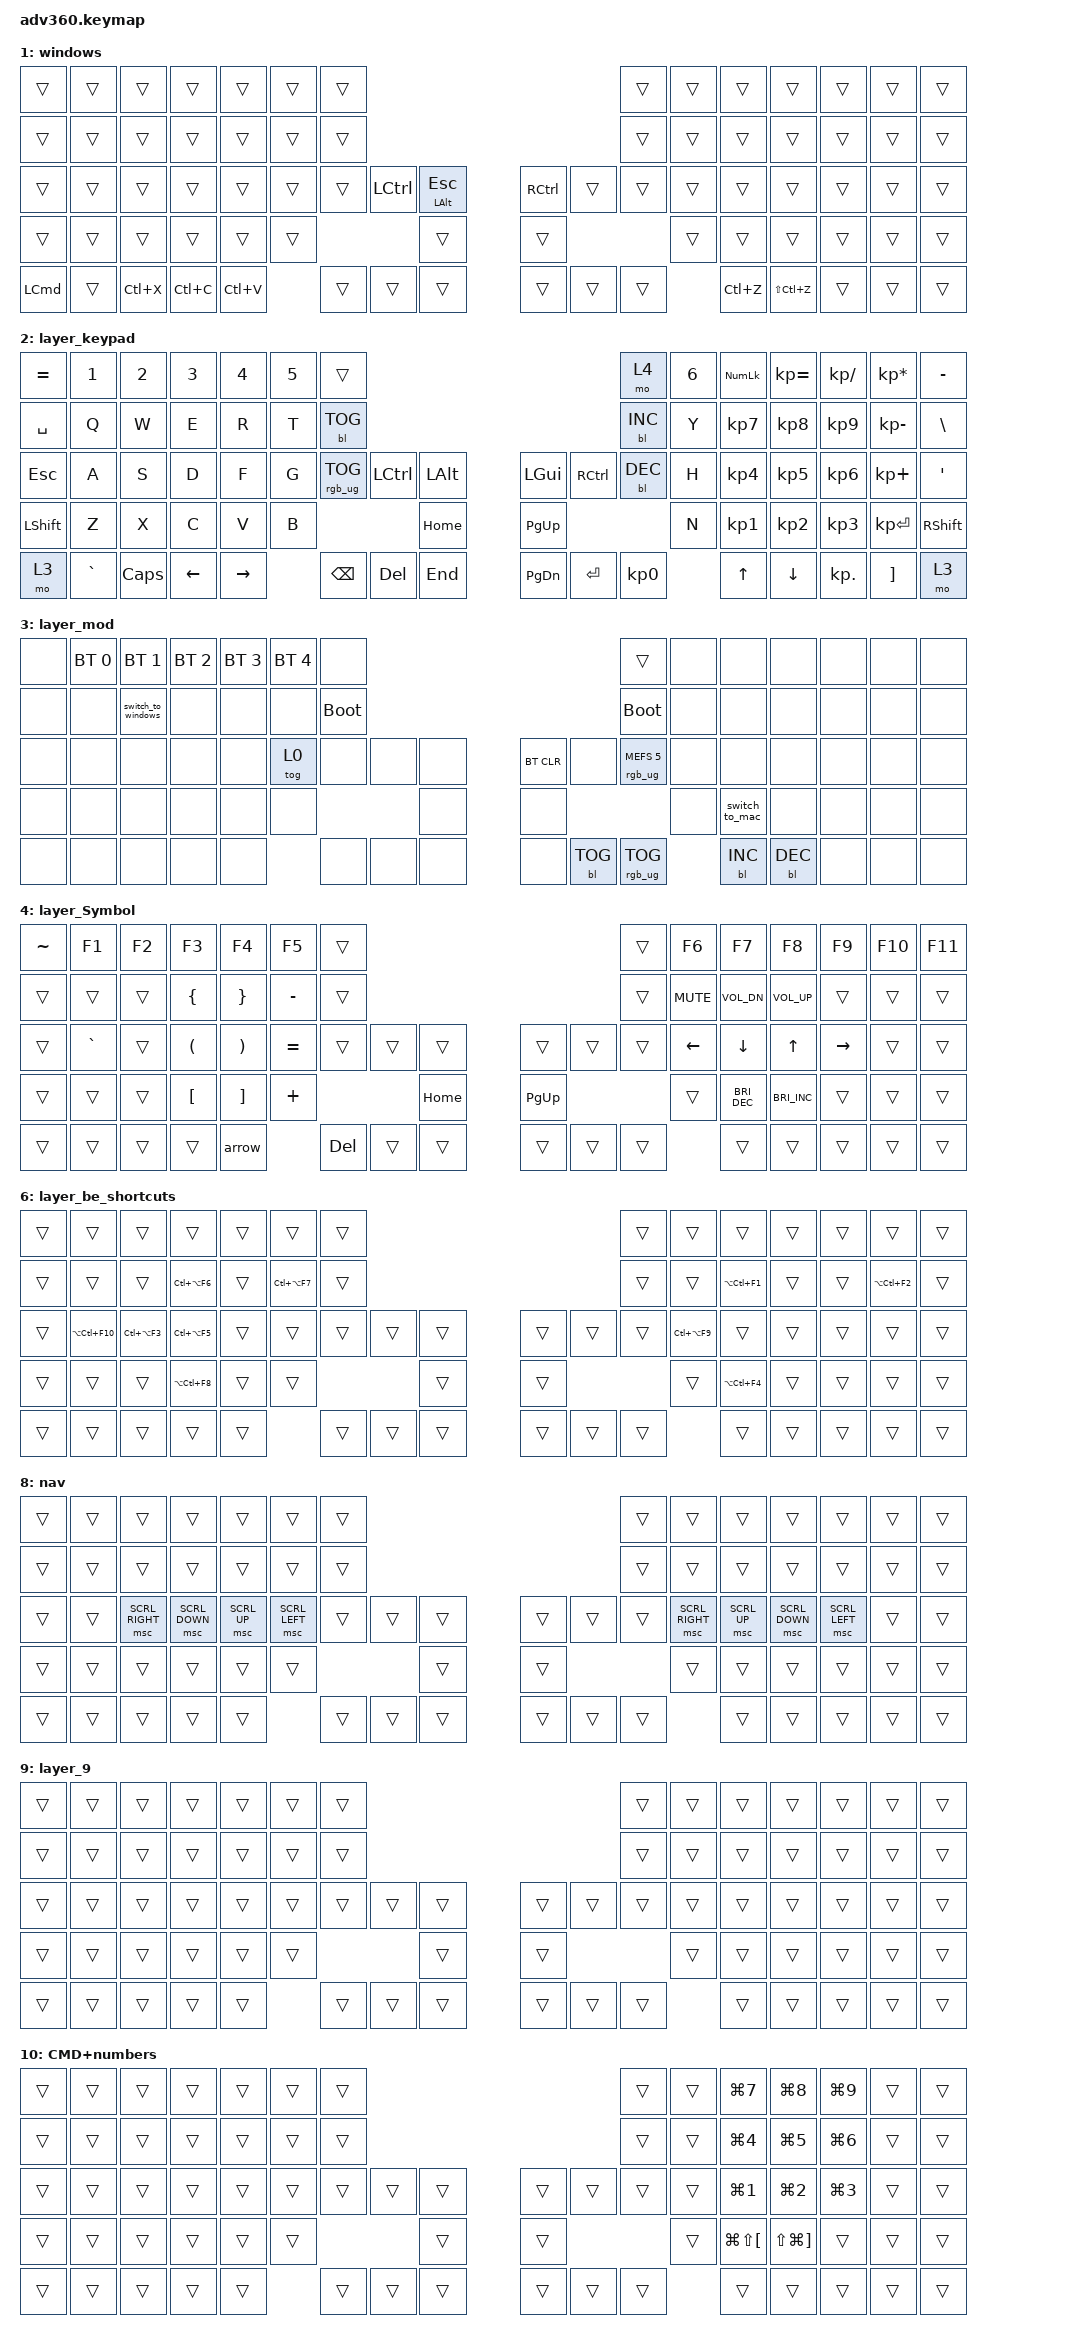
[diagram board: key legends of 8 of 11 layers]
/*
 * Copyright (c) 2020 The ZMK Contributors
 *
 * SPDX-License-Identifier: MIT
 */
/* THIS FILE WAS GENERATED!
 *
 * This file was generated automatically. You may or may not want to
 * edit it directly.
 */

#define ZMK_POINTING_DEFAULT_SCRL_VAL 40

#include <dt-bindings/zmk/mouse.h>
#include <dt-bindings/zmk/stp.h>
#include <behaviors.dtsi>
#include <dt-bindings/zmk/backlight.h>
#include <dt-bindings/zmk/bt.h>
#include <dt-bindings/zmk/keys.h>
#include <dt-bindings/zmk/pointing.h>
#include <dt-bindings/zmk/rgb.h>

&lt {
    quick-tap-ms = <150>;
    tapping-term-ms = <100>;
};

/ {
    behaviors {
        #include "macros.dtsi"
      #include "version.dtsi"
      #ifndef VERSION_MACRO

        macro_ver: macro_ver {
            compatible = "zmk,behavior-macro";
            label = "macro_version";
            #binding-cells = <0>;
            bindings = <&kp RET>;
        };

        #endif

        hm: homerow_mods {
            compatible = "zmk,behavior-hold-tap";
            label = "HOMEROW_MODS";
            #binding-cells = <2>;
            tapping-term-ms = <200>;
            quick_tap_ms = <175>;
            flavor = "tap-preferred";
            bindings = <&kp>, <&kp>;
        };

        tap_dance_shift_caps_word: tap_dance_shift_caps_word {
            compatible = "zmk,behavior-tap-dance";
            label = "TAP_DANCE_SHIFT_CAPS_WORD";
            #binding-cells = <0>;
            bindings = <&kp LEFT_SHIFT>, <&caps_word>;
        };

        urob: urob {
            compatible = "zmk,behavior-hold-tap";
            label = "UROB";
            bindings = <&kp>, <&kp>;

            #binding-cells = <2>;
            tapping-term-ms = <150>;
            quick-tap-ms = <175>;
            require-prior-idle-ms = <200>;
            flavor = "hold-preferred";
        };

        custom_mt: custom_mt {
            compatible = "zmk,behavior-hold-tap";
            label = "CUSTOM_MT";
            bindings = <&kp>, <&kp>;

            #binding-cells = <2>;
            tapping-term-ms = <200>;
            quick-tap-ms = <175>;
            require-prior-idle-ms = <350>;
            flavor = "hold-preferred";
        };

        pht: positional_hold_tap {
            compatible = "zmk,behavior-hold-tap";
            label = "POSITIONAL_HOLD_TAP";
            bindings = <&kp>, <&kp>;

            #binding-cells = <2>;
            tapping-term-ms = <400>;
            require-prior-idle-ms = <200>;
            quick-tap-ms = <175>;
            flavor = "hold-preferred";

            // hold-trigger-key-positions = <19 29>;    // <---[[the T, A key]]
        };

        mt_rt: mod_tap_retro_tap {
            compatible = "zmk,behavior-hold-tap";
            label = "MOD_TAP_RETRO_TAP";
            bindings = <&kp>, <&kp>;

            #binding-cells = <2>;
            retro-tap;
            flavor = "hold-preferred";
            tapping-term-ms = <200>;
        };

        mt_tp: mod_tap_tap_preferred {
            compatible = "zmk,behavior-hold-tap";
            label = "MOD_TAP_TAP_PREFERRED";
            bindings = <&kp>, <&kp>;

            #binding-cells = <2>;
            flavor = "tap-preferred";
            tapping-term-ms = <200>;
        };

        mt_100ms: mod_tap_100ms {
            compatible = "zmk,behavior-hold-tap";
            label = "MOD_TAP_100ms";
            bindings = <&kp>, <&kp>;

            #binding-cells = <2>;
            flavor = "hold-preferred";
            tapping-term-ms = <150>;
        };

        tap_dance_backspace: tap_dance_backspace {
            compatible = "zmk,behavior-tap-dance";
            label = "TAP_DANCE_BACKSPACE";
            #binding-cells = <0>;
            bindings =
                <&kp BACKSPACE>,
                <&kp LA(BACKSPACE)>,
                <&kp LG(BACKSPACE)>;

            tapping-term-ms = <150>;
        };

        shift_backspace_del_word: shift_backspace_del_word {
            compatible = "zmk,behavior-mod-morph";
            label = "SHIFT_BACKSPACE_DEL_WORD";
            bindings = <&kp BACKSPACE>, <&kp LA(BACKSPACE)>;

            #binding-cells = <0>;
            mods = <(MOD_RSFT)>;
        };
    };

    macros {
        arrow: arrow2 {
            compatible = "zmk,behavior-macro";
            #binding-cells = <0>;
            bindings = <&kp SPACE &kp EQUAL &kp GREATER_THAN &kp SPACE>;
            label = "ARROW2";
        };

        switch_to_windows: windows {
            compatible = "zmk,behavior-macro";
            #binding-cells = <0>;
            bindings = <&tog 1 &bt BT_SEL 2>;
            label = "WINDOWS";
        };

        switch_to_mac: mac {
            compatible = "zmk,behavior-macro";
            #binding-cells = <0>;
            bindings = <&tog 1 &bt BT_SEL 0>;
            label = "MAC";
        };

        double_click: double_click {
            compatible = "zmk,behavior-macro";
            #binding-cells = <0>;
            bindings = <&mkp MB1 &mkp MB1>;
            label = "DOUBLE_CLICK";
        };

        cmd_tab: cmd_tab {
            compatible = "zmk,behavior-macro";
            #binding-cells = <0>;
            bindings =
                <&macro_press>,
                <&kp LCMD>,
                <&macro_tap>,
                <&kp TAB>,
                <&macro_tap>,
                <&sk LCMD>,
                <&macro_release>,
                <&kp LCMD>;

            label = "CMD_TAB";
            tap-ms = <40>;
            wait-ms = <100>;
        };
    };

    combos {
        compatible = "zmk,combos";

        DF {
            bindings = <&kp ESCAPE>;
            key-positions = <32 31>;
            layers = <0 1 4>;
            timeout-ms = <20>;
            require-prior-idle-ms = <125>;
        };

        SD {
            bindings = <&mkp MB2>;
            key-positions = <30 31>;
            layers = <0 1>;
            timeout-ms = <20>;
            require-prior-idle-ms = <125>;
        };

        FG {
            bindings = <&double_click>;
            key-positions = <33 32>;
            timeout-ms = <20>;
            require-prior-idle-ms = <125>;
        };

        VB {
            bindings = <&sl 6>;
            key-positions = <50 51>;
            timeout-ms = <20>;
            require-prior-idle-ms = <125>;
        };

        FE {
            bindings = <&sl 5>;
            key-positions = <32 17>;
            timeout-ms = <20>;
            layers = <0 2 1 3 4 5 7 6>;
            require-prior-idle-ms = <125>;
        };

        CV {
            bindings = <&sl 10>;
            key-positions = <49 50>;
        };

        JK {
            bindings = <&kp ESCAPE>;
            key-positions = <41 42>;
            timeout-ms = <20>;
            require-prior-idle-ms = <125>;
            layers = <0 4>;
        };

        ER {
            bindings = <&kp LCTRL>;
            key-positions = <17 18>;
            layers = <0 1 4>;
            require-prior-idle-ms = <125>;
            timeout-ms = <20>;
        };

        UI {
            bindings = <&kp LCTRL>;
            key-positions = <23 24>;
            layers = <0 1 4>;
            require-prior-idle-ms = <125>;
            timeout-ms = <20>;
        };
    };

    keymap {
        compatible = "zmk,keymap";

        default_layer {
            bindings = <
&kp TILDE                   &kp N1    &kp N2     &kp N3     &kp N4     &kp N5  &tog 2                                                                                                                &mo 3                       &kp N6  &kp N7     &kp N8         &kp N9    &kp N0    &kp MINUS
&kp LCTRL                   &kp Q     &kp W      &kp E      &kp R      &kp T   &kp LS(TAB)                                                                                                           &kp LG(GRAVE)               &kp Y   &kp U      &kp I          &kp O     &kp P     &kp BSLH
&kp LA(LC(LG(LEFT_SHIFT)))  &kp A     &kp S      &kp D      &kp F      &kp G   &kp TAB                         &kp LCMD                  &kp LALT              &kp RIGHT_ALT      &kp RIGHT_COMMAND  &kp LG(TILDE)               &kp H   &kp J      &kp K          &kp L     &kp SEMI  &urob LA(LC(LG(LEFT_SHIFT))) SQT
&kp LEFT_SHIFT              &kp Z     &kp X      &kp C      &kp V      &kp B                                                             &kp LS(LEFT_ALT)      &kp PLUS                                                          &kp N   &kp M      &kp COMMA      &kp DOT   &kp FSLH  &kp RSHFT
&kp LEFT_CONTROL            &kp CAPS  &kp LG(X)  &kp LG(C)  &kp LG(V)          &custom_mt LS(LCTRL) BACKSPACE  &kp LS(LA(LEFT_CONTROL))  &kp SINGLE_QUOTE      &kp DOUBLE_QUOTES  &lt 4 ENTER        &custom_mt LS(LCTRL) SPACE          &kp LG(Z)  &kp LG(LS(Z))  &kp LBKT  &kp RBKT  &kp RIGHT_CONTROL
            >;
        };

        windows {
            bindings = <
&trans            &trans  &trans     &trans     &trans     &trans  &trans                                                                 &trans  &trans  &trans     &trans         &trans  &trans  &trans
&trans            &trans  &trans     &trans     &trans     &trans  &trans                                                                 &trans  &trans  &trans     &trans         &trans  &trans  &trans
&trans            &trans  &trans     &trans     &trans     &trans  &trans  &kp LCTRL  &mt LEFT_ALT ESCAPE      &kp RIGHT_CONTROL  &trans  &trans  &trans  &trans     &trans         &trans  &trans  &trans
&trans            &trans  &trans     &trans     &trans     &trans                     &trans                   &trans                             &trans  &trans     &trans         &trans  &trans  &trans
&kp LEFT_COMMAND  &trans  &kp LC(X)  &kp LC(C)  &kp LC(V)          &trans  &trans     &trans                   &trans             &trans  &trans          &kp LC(Z)  &kp LS(LC(Z))  &trans  &trans  &trans
            >;
        };

        layer_keypad {
            bindings = <
&kp EQUAL  &kp N1     &kp N2    &kp N3    &kp N4     &kp N5  &trans                                                          &mo 4       &kp N6  &kp KP_NUM  &kp KP_EQUAL  &kp KP_DIVIDE  &kp KP_MULTIPLY  &kp MINUS
&kp SPACE  &kp Q      &kp W     &kp E     &kp R      &kp T   &bl BL_TOG                                                      &bl BL_INC  &kp Y   &kp KP_N7   &kp KP_N8     &kp KP_N9      &kp KP_MINUS     &kp BSLH
&kp ESC    &kp A      &kp S     &kp D     &kp F      &kp G   &rgb_ug RGB_TOG  &kp LCTRL  &kp LALT      &kp LGUI   &kp RCTRL  &bl BL_DEC  &kp H   &kp KP_N4   &kp KP_N5     &kp KP_N6      &kp KP_PLUS      &kp SQT
&kp LSHFT  &kp Z      &kp X     &kp C     &kp V      &kp B                               &kp HOME      &kp PG_UP                         &kp N   &kp KP_N1   &kp KP_N2     &kp KP_N3      &kp KP_ENTER     &kp RSHFT
&mo 3      &kp GRAVE  &kp CAPS  &kp LEFT  &kp RIGHT          &kp BSPC         &kp DEL    &kp END       &kp PG_DN  &kp ENTER  &kp KP_N0           &kp UP      &kp DOWN      &kp KP_DOT     &kp RBKT         &mo 3
            >;
        };

        layer_mod {
            bindings = <
&none  &bt BT_SEL 0  &bt BT_SEL 1        &bt BT_SEL 2  &bt BT_SEL 3  &bt BT_SEL 4  &none                                                  &trans                  &none  &none           &none       &none  &none  &none
&none  &none         &switch_to_windows  &none         &none         &none         &bootloader                                            &bootloader             &none  &none           &none       &none  &none  &none
&none  &none         &none               &none         &none         &tog 0        &none        &none  &none      &bt BT_CLR  &none       &rgb_ug RGB_MEFS_CMD 5  &none  &none           &none       &none  &none  &none
&none  &none         &none               &none         &none         &none                             &none      &none                                           &none  &switch_to_mac  &none       &none  &none  &none
&none  &none         &none               &none         &none                       &none        &none  &none      &none       &bl BL_TOG  &rgb_ug RGB_TOG                &bl BL_INC      &bl BL_DEC  &none  &none  &none
            >;
        };

        layer_Symbol {
            bindings = <
&kp TILDE  &kp F1     &kp F2  &kp F3                &kp F4                 &kp F5     &trans                                              &trans  &kp F6          &kp F7                &kp F8                &kp F9           &kp F10  &kp F11
&trans     &trans     &trans  &kp LEFT_BRACE        &kp RIGHT_BRACE        &kp MINUS  &trans                                              &trans  &kp C_MUTE      &kp C_VOL_DN          &kp C_VOL_UP          &trans           &trans   &trans
&trans     &kp GRAVE  &trans  &kp LEFT_PARENTHESIS  &kp RIGHT_PARENTHESIS  &kp EQUAL  &trans   &trans  &trans        &trans       &trans  &trans  &kp LEFT_ARROW  &kp DOWN_ARROW        &kp UP_ARROW          &kp RIGHT_ARROW  &trans   &trans
&trans     &trans     &trans  &kp LEFT_BRACKET      &kp RIGHT_BRACKET      &kp PLUS                    &kp HOME      &kp PAGE_UP                  &trans          &kp C_BRIGHTNESS_DEC  &kp C_BRIGHTNESS_INC  &trans           &trans   &trans
&trans     &trans     &trans  &trans                &arrow                            &kp DEL  &trans  &trans        &trans       &trans  &trans                  &trans                &trans                &trans           &trans   &trans
            >;
        };

        layer_fe_shortcuts {
            bindings = <
&trans  &trans                   &trans                  &trans                  &trans  &trans                  &trans                                      &trans  &trans                  &trans                  &trans  &trans  &trans                  &trans
&trans  &trans                   &trans                  &kp LS(LG(LC(LA(F6))))  &trans  &kp LS(LC(LA(LG(F7))))  &trans                                      &trans  &trans                  &kp LS(LA(LC(LG(F1))))  &trans  &trans  &kp LS(LG(LA(LC(F2))))  &trans
&trans  &kp LS(LA(LC(LG(F10))))  &kp LS(LC(LA(LG(F3))))  &kp LS(LG(LC(LA(F5))))  &trans  &trans                  &trans  &trans  &trans      &trans  &trans  &trans  &kp LS(LC(LG(LA(F9))))  &trans                  &trans  &trans  &trans                  &trans
&trans  &trans                   &trans                  &kp LS(LA(LG(LC(F8))))  &trans  &trans                                  &trans      &trans                  &trans                  &kp LS(LG(LA(LC(F4))))  &trans  &trans  &trans                  &trans
&trans  &trans                   &trans                  &trans                  &trans                          &trans  &trans  &trans      &trans  &trans  &trans                          &trans                  &trans  &trans  &trans                  &trans
            >;
        };

        layer_be_shortcuts {
            bindings = <
&trans  &trans           &trans          &trans          &trans  &trans          &trans                                      &trans  &trans          &trans          &trans  &trans  &trans          &trans
&trans  &trans           &trans          &kp LC(LA(F6))  &trans  &kp LC(LA(F7))  &trans                                      &trans  &trans          &kp LA(LC(F1))  &trans  &trans  &kp LA(LC(F2))  &trans
&trans  &kp LA(LC(F10))  &kp LC(LA(F3))  &kp LC(LA(F5))  &trans  &trans          &trans  &trans  &trans      &trans  &trans  &trans  &kp LC(LA(F9))  &trans          &trans  &trans  &trans          &trans
&trans  &trans           &trans          &kp LA(LC(F8))  &trans  &trans                          &trans      &trans                  &trans          &kp LA(LC(F4))  &trans  &trans  &trans          &trans
&trans  &trans           &trans          &trans          &trans                  &trans  &trans  &trans      &trans  &trans  &trans                  &trans          &trans  &trans  &trans          &trans
            >;
        };

        layer_platform_shortcuts {
            bindings = <
&trans  &trans  &trans                   &trans                   &trans           &trans           &trans                                      &trans  &trans  &trans  &trans  &trans  &trans  &trans
&trans  &trans  &trans                   &kp LS(LA(LG(LC(F12))))  &kp LC(LA(F11))  &trans           &trans                                      &trans  &trans  &trans  &trans  &trans  &trans  &trans
&trans  &trans  &kp LS(LG(LC(LA(F11))))  &kp LS(LA(LC(LG(F13))))  &trans           &kp LA(LC(F12))  &trans  &trans  &trans      &trans  &trans  &trans  &trans  &trans  &trans  &trans  &trans  &trans
&trans  &trans  &trans                   &trans                   &trans           &trans                           &trans      &trans                  &trans  &trans  &trans  &trans  &trans  &trans
&trans  &trans  &trans                   &trans                   &trans                            &trans  &trans  &trans      &trans  &trans  &trans          &trans  &trans  &trans  &trans  &trans
            >;
        };

        nav {
            bindings = <
&trans  &trans  &trans           &trans          &trans        &trans          &trans                                      &trans  &trans           &trans        &trans          &trans          &trans  &trans
&trans  &trans  &trans           &trans          &trans        &trans          &trans                                      &trans  &trans           &trans        &trans          &trans          &trans  &trans
&trans  &trans  &msc SCRL_RIGHT  &msc SCRL_DOWN  &msc SCRL_UP  &msc SCRL_LEFT  &trans  &trans  &trans      &trans  &trans  &trans  &msc SCRL_RIGHT  &msc SCRL_UP  &msc SCRL_DOWN  &msc SCRL_LEFT  &trans  &trans
&trans  &trans  &trans           &trans          &trans        &trans                          &trans      &trans                  &trans           &trans        &trans          &trans          &trans  &trans
&trans  &trans  &trans           &trans          &trans                        &trans  &trans  &trans      &trans  &trans  &trans                   &trans        &trans          &trans          &trans  &trans
            >;
        };

        layer_9 {
            bindings = <
&trans  &trans  &trans  &trans  &trans  &trans  &trans                                      &trans  &trans  &trans  &trans  &trans  &trans  &trans
&trans  &trans  &trans  &trans  &trans  &trans  &trans                                      &trans  &trans  &trans  &trans  &trans  &trans  &trans
&trans  &trans  &trans  &trans  &trans  &trans  &trans  &trans  &trans      &trans  &trans  &trans  &trans  &trans  &trans  &trans  &trans  &trans
&trans  &trans  &trans  &trans  &trans  &trans                  &trans      &trans                  &trans  &trans  &trans  &trans  &trans  &trans
&trans  &trans  &trans  &trans  &trans          &trans  &trans  &trans      &trans  &trans  &trans          &trans  &trans  &trans  &trans  &trans
            >;
        };

        CMD+numbers {
            bindings = <
&trans  &trans  &trans  &trans  &trans  &trans  &trans                                      &trans  &trans  &kp LG(NUMBER_7)          &kp LG(N8)                 &kp LG(NUMBER_9)  &trans  &trans
&trans  &trans  &trans  &trans  &trans  &trans  &trans                                      &trans  &trans  &kp LG(NUMBER_4)          &kp LG(N5)                 &kp LG(NUMBER_6)  &trans  &trans
&trans  &trans  &trans  &trans  &trans  &trans  &trans  &trans  &trans      &trans  &trans  &trans  &trans  &kp LG(NUMBER_1)          &kp LG(NUMBER_2)           &kp LG(NUMBER_3)  &trans  &trans
&trans  &trans  &trans  &trans  &trans  &trans                  &trans      &trans                  &trans  &kp LG(LS(LEFT_BRACKET))  &kp LS(LG(RIGHT_BRACKET))  &trans            &trans  &trans
&trans  &trans  &trans  &trans  &trans          &trans  &trans  &trans      &trans  &trans  &trans          &trans                    &trans                     &trans            &trans  &trans
            >;
        };
    };
};
